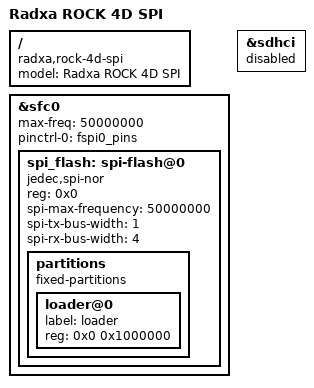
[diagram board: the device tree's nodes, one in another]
// SPDX-License-Identifier: (GPL-2.0+ OR MIT)
/*
 * Copyright (c) 2025 Rockchip Electronics Co., Ltd.
 * Copyright (c) 2025 Radxa Computer (Shenzhen) Co., Ltd.
 *
 */

/dts-v1/;

#include "rk3576-rock-4d.dts"

/ {
	model = "Radxa ROCK 4D SPI";
	compatible = "radxa,rock-4d-spi", "radxa,rock-4d", "rockchip,rk3576";
};

&sfc0 {
	status = "okay";
	max-freq = <50000000>;
	#address-cells = <1>;
	#size-cells = <0>;
	pinctrl-names = "default";
	pinctrl-0 = <&fspi0_pins>;

	spi_flash: spi-flash@0 {
		#address-cells = <1>;
		#size-cells = <0>;
		compatible = "jedec,spi-nor";
		reg = <0x0>;
		spi-max-frequency = <50000000>;
		spi-tx-bus-width = <1>;
		spi-rx-bus-width = <4>;
		status = "okay";

		partitions {
			compatible = "fixed-partitions";
			#address-cells = <1>;
			#size-cells = <1>;

			loader@0 {
				label = "loader";
				reg = <0x0 0x1000000>;
			};
		};
	};
};

&sdhci {
	status = "disabled";
};
